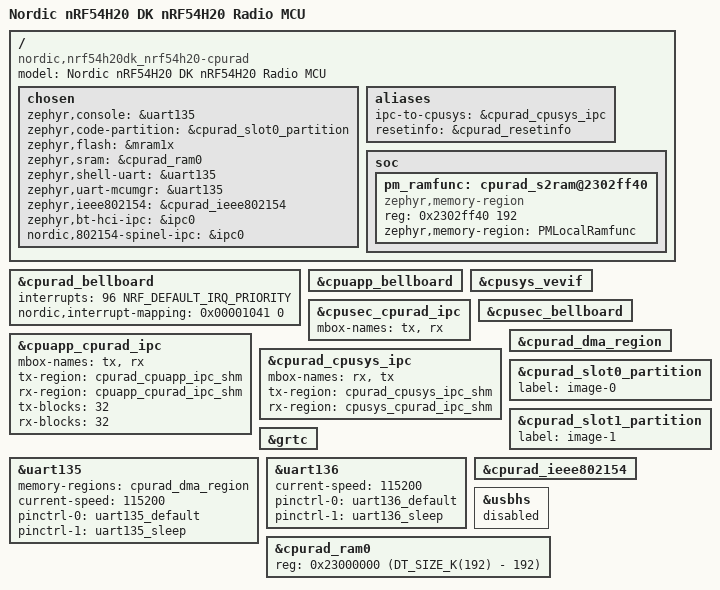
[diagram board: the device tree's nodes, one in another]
/*
 * Copyright (c) 2024 Nordic Semiconductor ASA
 *
 * SPDX-License-Identifier: Apache-2.0
 */

/dts-v1/;

#include <nordic/nrf54h20_cpurad.dtsi>
#include "nrf54h20dk_nrf54h20-common.dtsi"

/delete-node/ &cpuapp_cpuppr_ipc;
/delete-node/ &cpuapp_cpusys_ipc;
/delete-node/ &cpuapp_cpuflpr_ipc;
/delete-node/ &cpusec_cpuapp_ipc;

/ {
	compatible = "nordic,nrf54h20dk_nrf54h20-cpurad";
	model = "Nordic nRF54H20 DK nRF54H20 Radio MCU";

	chosen {
		zephyr,console = &uart135;
		zephyr,code-partition = &cpurad_slot0_partition;
		zephyr,flash = &mram1x;
		zephyr,sram = &cpurad_ram0;
		zephyr,shell-uart = &uart135;
		zephyr,uart-mcumgr = &uart135;
		zephyr,ieee802154 = &cpurad_ieee802154;
		zephyr,bt-hci-ipc = &ipc0;
		nordic,802154-spinel-ipc = &ipc0;
	};

	aliases {
		ipc-to-cpusys = &cpurad_cpusys_ipc;
		resetinfo = &cpurad_resetinfo;
	};
};

&cpurad_bellboard {
	status = "okay";
	interrupts = <96 NRF_DEFAULT_IRQ_PRIORITY>;
	interrupt-names = "irq0";
	/* irq0: 0: cpurad-cpusec, 6: cpurad-cpusys, 12: cpurad-cpuapp */
	nordic,interrupt-mapping = <0x00001041 0>;
};

&cpuapp_bellboard {
	status = "okay";
};

&cpusys_vevif {
	status = "okay";
};

&cpusec_cpurad_ipc {
	status = "okay";
	mbox-names = "tx", "rx";
};

&cpusec_bellboard {
	status = "okay";
};

ipc0: &cpuapp_cpurad_ipc {
	status = "okay";
	mbox-names = "tx", "rx";
	tx-region = <&cpurad_cpuapp_ipc_shm>;
	rx-region = <&cpuapp_cpurad_ipc_shm>;
	tx-blocks = <32>;
	rx-blocks = <32>;
};

&cpurad_cpusys_ipc {
	status = "okay";
	mbox-names = "rx", "tx";
	tx-region = <&cpurad_cpusys_ipc_shm>;
	rx-region = <&cpusys_cpurad_ipc_shm>;
};

&cpurad_dma_region {
	status = "okay";
};

slot0_partition: &cpurad_slot0_partition {
	label = "image-0";
};

secondary_app_partition: &cpurad_slot1_partition {};

slot1_partition: &cpurad_slot1_partition {
	label = "image-1";
};

&grtc {
	status = "okay";
};

&uart135 {
	status = "okay";
	memory-regions = <&cpurad_dma_region>;
	current-speed = <115200>;
	pinctrl-0 = <&uart135_default>;
	pinctrl-1 = <&uart135_sleep>;
	pinctrl-names = "default", "sleep";
};

&uart136 {
	current-speed = <115200>;
	pinctrl-0 = <&uart136_default>;
	pinctrl-1 = <&uart136_sleep>;
	pinctrl-names = "default", "sleep";
};

&cpurad_ieee802154 {
	status = "okay";
};

zephyr_udc0: &usbhs {
	status = "disabled";
};

/* Trim this RAM block for power management related features. */
&cpurad_ram0 {
	reg = <0x23000000 (DT_SIZE_K(192) - 192)>;
	ranges = <0x0 0x23000000 (0x30000 - 0xC0)>;
};

/ {
	soc {
		/* cache control functions - must be executed from RAM */
		pm_ramfunc: cpurad_s2ram@2302ff40 {
			compatible = "zephyr,memory-region", "mmio-sram";
			reg = <0x2302ff40 192>;
			zephyr,memory-region = "PMLocalRamfunc";
		};
	};
};
